VERSION "Accord 9G AU Radar BUS 1"

NS_ :

BS_:

BU_: RADAR ADAS EON

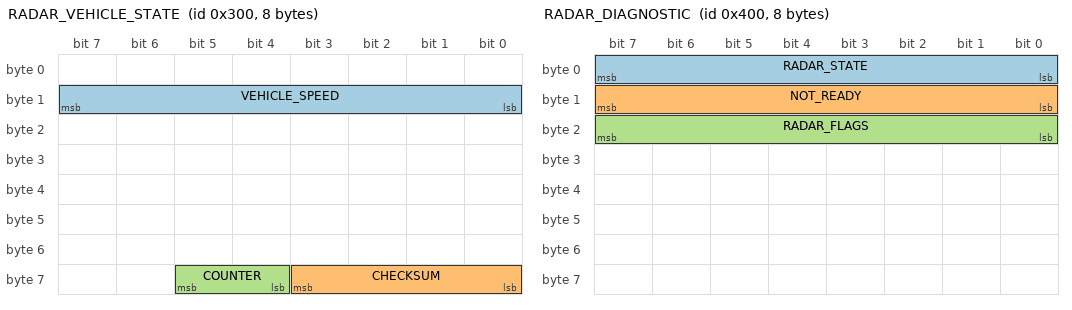
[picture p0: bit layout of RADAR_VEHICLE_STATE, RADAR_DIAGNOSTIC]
BO_ 768 RADAR_VEHICLE_STATE: 8 ADAS
 SG_ VEHICLE_SPEED : 15|8@0+ (1,0) [0|255] "kph" RADAR
 SG_ CHECKSUM : 59|4@0+ (1,0) [0|15] "" RADAR
 SG_ COUNTER : 61|2@0+ (1,0) [0|3] "" RADAR

BO_ 769 RADAR_VEHICLE_STATE2: 8 ADAS

BO_ 1024 RADAR_DIAGNOSTIC: 8 RADAR
 SG_ RADAR_STATE : 7|8@0+ (1,0) [0|255] "" EON
 SG_ NOT_READY : 15|8@0+ (1,0) [0|255] "" EON
 SG_ RADAR_FLAGS : 23|8@0+ (1,0) [0|255] "" EON

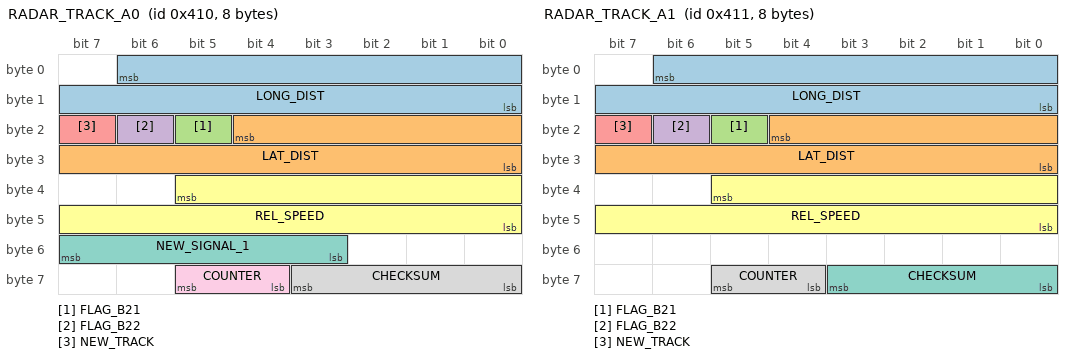
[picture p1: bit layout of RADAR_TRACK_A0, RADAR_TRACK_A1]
BO_ 1040 RADAR_TRACK_A0: 8 RADAR
 SG_ LONG_DIST : 6|15@0+ (0.0078125,0) [0|255.99] "m" EON
 SG_ LAT_DIST : 20|13@0- (0.0078125,0) [-32|32] "m" EON
 SG_ FLAG_B21 : 21|1@0+ (1,0) [0|1] "" EON
 SG_ FLAG_B22 : 22|1@0+ (1,0) [0|1] "" EON
 SG_ NEW_TRACK : 23|1@0+ (1,0) [0|1] "" EON
 SG_ REL_SPEED : 37|14@0- (0.0078125,0) [-64|64] "m/s" EON
 SG_ NEW_SIGNAL_1 : 55|5@0+ (1,0) [0|31] "" XXX
 SG_ CHECKSUM : 59|4@0+ (1,0) [0|15] "" EON
 SG_ COUNTER : 61|2@0+ (1,0) [0|3] "" EON

BO_ 1041 RADAR_TRACK_A1: 8 RADAR
 SG_ LONG_DIST : 6|15@0+ (0.0078125,0) [0|255.99] "m" EON
 SG_ LAT_DIST : 20|13@0- (0.0078125,0) [-32|32] "m" EON
 SG_ FLAG_B21 : 21|1@0+ (1,0) [0|1] "" EON
 SG_ FLAG_B22 : 22|1@0+ (1,0) [0|1] "" EON
 SG_ NEW_TRACK : 23|1@0+ (1,0) [0|1] "" EON
 SG_ REL_SPEED : 37|14@0- (0.0078125,0) [-64|64] "m/s" EON
 SG_ CHECKSUM : 59|4@0+ (1,0) [0|15] "" EON
 SG_ COUNTER : 61|2@0+ (1,0) [0|3] "" EON

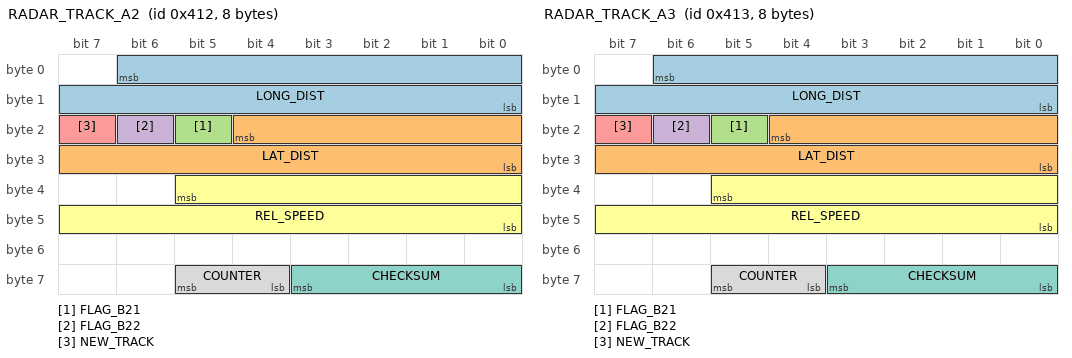
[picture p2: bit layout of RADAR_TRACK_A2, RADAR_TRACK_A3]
BO_ 1042 RADAR_TRACK_A2: 8 RADAR
 SG_ LONG_DIST : 6|15@0+ (0.0078125,0) [0|255.99] "m" EON
 SG_ LAT_DIST : 20|13@0- (0.0078125,0) [-32|32] "m" EON
 SG_ FLAG_B21 : 21|1@0+ (1,0) [0|1] "" EON
 SG_ FLAG_B22 : 22|1@0+ (1,0) [0|1] "" EON
 SG_ NEW_TRACK : 23|1@0+ (1,0) [0|1] "" EON
 SG_ REL_SPEED : 37|14@0- (0.0078125,0) [-64|64] "m/s" EON
 SG_ CHECKSUM : 59|4@0+ (1,0) [0|15] "" EON
 SG_ COUNTER : 61|2@0+ (1,0) [0|3] "" EON

BO_ 1043 RADAR_TRACK_A3: 8 RADAR
 SG_ LONG_DIST : 6|15@0+ (0.0078125,0) [0|255.99] "m" EON
 SG_ LAT_DIST : 20|13@0- (0.0078125,0) [-32|32] "m" EON
 SG_ FLAG_B21 : 21|1@0+ (1,0) [0|1] "" EON
 SG_ FLAG_B22 : 22|1@0+ (1,0) [0|1] "" EON
 SG_ NEW_TRACK : 23|1@0+ (1,0) [0|1] "" EON
 SG_ REL_SPEED : 37|14@0- (0.0078125,0) [-64|64] "m/s" EON
 SG_ CHECKSUM : 59|4@0+ (1,0) [0|15] "" EON
 SG_ COUNTER : 61|2@0+ (1,0) [0|3] "" EON

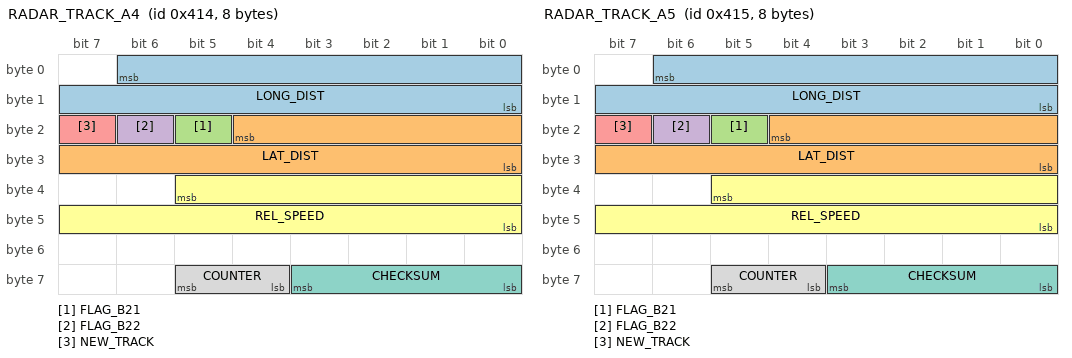
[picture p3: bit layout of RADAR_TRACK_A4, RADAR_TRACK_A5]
BO_ 1044 RADAR_TRACK_A4: 8 RADAR
 SG_ LONG_DIST : 6|15@0+ (0.0078125,0) [0|255.99] "m" EON
 SG_ LAT_DIST : 20|13@0- (0.0078125,0) [-32|32] "m" EON
 SG_ FLAG_B21 : 21|1@0+ (1,0) [0|1] "" EON
 SG_ FLAG_B22 : 22|1@0+ (1,0) [0|1] "" EON
 SG_ NEW_TRACK : 23|1@0+ (1,0) [0|1] "" EON
 SG_ REL_SPEED : 37|14@0- (0.0078125,0) [-64|64] "m/s" EON
 SG_ CHECKSUM : 59|4@0+ (1,0) [0|15] "" EON
 SG_ COUNTER : 61|2@0+ (1,0) [0|3] "" EON

BO_ 1045 RADAR_TRACK_A5: 8 RADAR
 SG_ LONG_DIST : 6|15@0+ (0.0078125,0) [0|255.99] "m" EON
 SG_ LAT_DIST : 20|13@0- (0.0078125,0) [-32|32] "m" EON
 SG_ FLAG_B21 : 21|1@0+ (1,0) [0|1] "" EON
 SG_ FLAG_B22 : 22|1@0+ (1,0) [0|1] "" EON
 SG_ NEW_TRACK : 23|1@0+ (1,0) [0|1] "" EON
 SG_ REL_SPEED : 37|14@0- (0.0078125,0) [-64|64] "m/s" EON
 SG_ CHECKSUM : 59|4@0+ (1,0) [0|15] "" EON
 SG_ COUNTER : 61|2@0+ (1,0) [0|3] "" EON

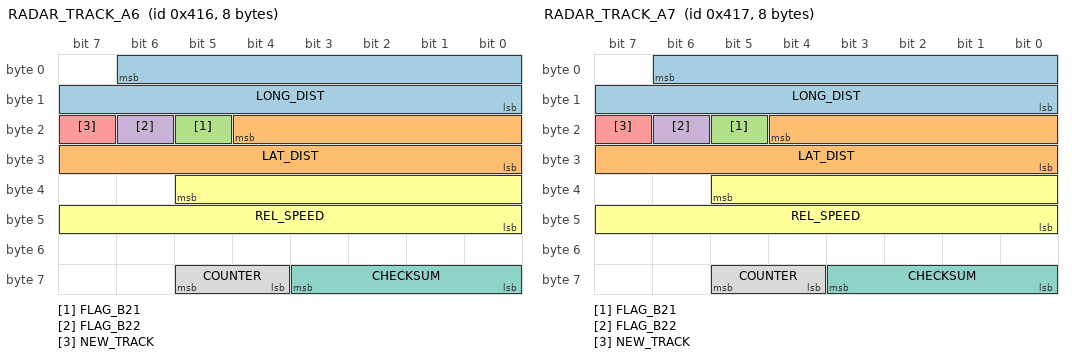
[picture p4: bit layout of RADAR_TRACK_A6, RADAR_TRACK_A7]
BO_ 1046 RADAR_TRACK_A6: 8 RADAR
 SG_ LONG_DIST : 6|15@0+ (0.0078125,0) [0|255.99] "m" EON
 SG_ LAT_DIST : 20|13@0- (0.0078125,0) [-32|32] "m" EON
 SG_ FLAG_B21 : 21|1@0+ (1,0) [0|1] "" EON
 SG_ FLAG_B22 : 22|1@0+ (1,0) [0|1] "" EON
 SG_ NEW_TRACK : 23|1@0+ (1,0) [0|1] "" EON
 SG_ REL_SPEED : 37|14@0- (0.0078125,0) [-64|64] "m/s" EON
 SG_ CHECKSUM : 59|4@0+ (1,0) [0|15] "" EON
 SG_ COUNTER : 61|2@0+ (1,0) [0|3] "" EON

BO_ 1047 RADAR_TRACK_A7: 8 RADAR
 SG_ LONG_DIST : 6|15@0+ (0.0078125,0) [0|255.99] "m" EON
 SG_ LAT_DIST : 20|13@0- (0.0078125,0) [-32|32] "m" EON
 SG_ FLAG_B21 : 21|1@0+ (1,0) [0|1] "" EON
 SG_ FLAG_B22 : 22|1@0+ (1,0) [0|1] "" EON
 SG_ NEW_TRACK : 23|1@0+ (1,0) [0|1] "" EON
 SG_ REL_SPEED : 37|14@0- (0.0078125,0) [-64|64] "m/s" EON
 SG_ CHECKSUM : 59|4@0+ (1,0) [0|15] "" EON
 SG_ COUNTER : 61|2@0+ (1,0) [0|3] "" EON

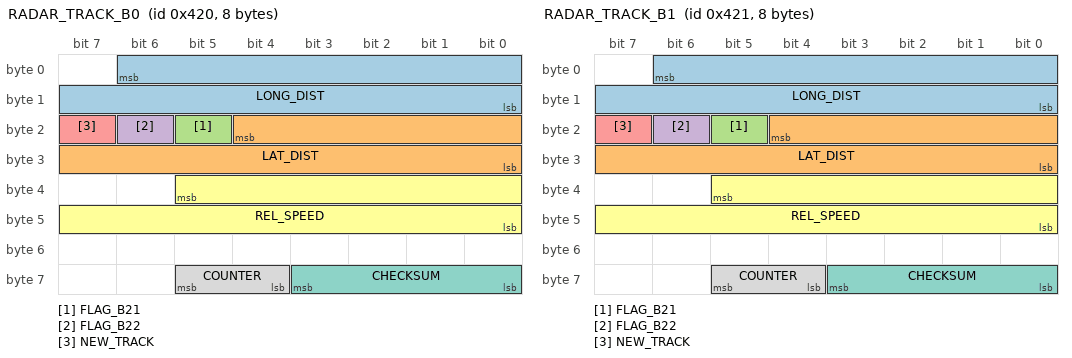
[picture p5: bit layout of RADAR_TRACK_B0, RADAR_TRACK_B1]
BO_ 1056 RADAR_TRACK_B0: 8 RADAR
 SG_ LONG_DIST : 6|15@0+ (0.0078125,0) [0|255.99] "m" EON
 SG_ LAT_DIST : 20|13@0- (0.0078125,0) [-32|32] "m" EON
 SG_ FLAG_B21 : 21|1@0+ (1,0) [0|1] "" EON
 SG_ FLAG_B22 : 22|1@0+ (1,0) [0|1] "" EON
 SG_ NEW_TRACK : 23|1@0+ (1,0) [0|1] "" EON
 SG_ REL_SPEED : 37|14@0- (0.0078125,0) [-64|64] "m/s" EON
 SG_ CHECKSUM : 59|4@0+ (1,0) [0|15] "" EON
 SG_ COUNTER : 61|2@0+ (1,0) [0|3] "" EON

BO_ 1057 RADAR_TRACK_B1: 8 RADAR
 SG_ LONG_DIST : 6|15@0+ (0.0078125,0) [0|255.99] "m" EON
 SG_ LAT_DIST : 20|13@0- (0.0078125,0) [-32|32] "m" EON
 SG_ FLAG_B21 : 21|1@0+ (1,0) [0|1] "" EON
 SG_ FLAG_B22 : 22|1@0+ (1,0) [0|1] "" EON
 SG_ NEW_TRACK : 23|1@0+ (1,0) [0|1] "" EON
 SG_ REL_SPEED : 37|14@0- (0.0078125,0) [-64|64] "m/s" EON
 SG_ CHECKSUM : 59|4@0+ (1,0) [0|15] "" EON
 SG_ COUNTER : 61|2@0+ (1,0) [0|3] "" EON

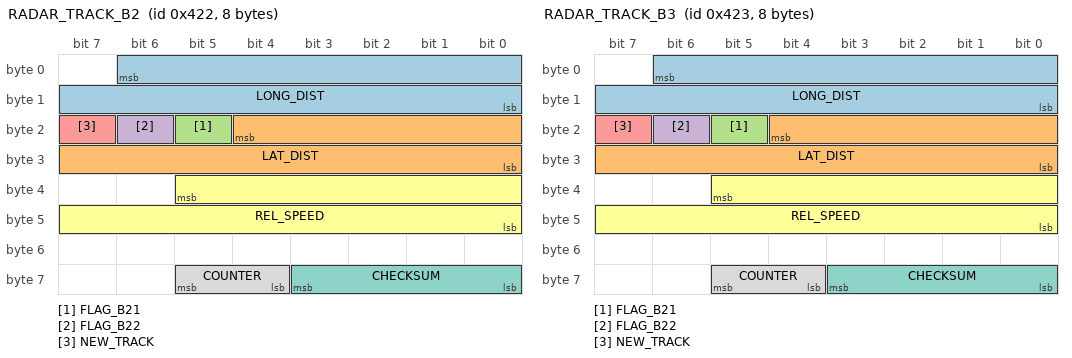
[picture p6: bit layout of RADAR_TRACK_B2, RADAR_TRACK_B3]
BO_ 1058 RADAR_TRACK_B2: 8 RADAR
 SG_ LONG_DIST : 6|15@0+ (0.0078125,0) [0|255.99] "m" EON
 SG_ LAT_DIST : 20|13@0- (0.0078125,0) [-32|32] "m" EON
 SG_ FLAG_B21 : 21|1@0+ (1,0) [0|1] "" EON
 SG_ FLAG_B22 : 22|1@0+ (1,0) [0|1] "" EON
 SG_ NEW_TRACK : 23|1@0+ (1,0) [0|1] "" EON
 SG_ REL_SPEED : 37|14@0- (0.0078125,0) [-64|64] "m/s" EON
 SG_ CHECKSUM : 59|4@0+ (1,0) [0|15] "" EON
 SG_ COUNTER : 61|2@0+ (1,0) [0|3] "" EON

BO_ 1059 RADAR_TRACK_B3: 8 RADAR
 SG_ LONG_DIST : 6|15@0+ (0.0078125,0) [0|255.99] "m" EON
 SG_ LAT_DIST : 20|13@0- (0.0078125,0) [-32|32] "m" EON
 SG_ FLAG_B21 : 21|1@0+ (1,0) [0|1] "" EON
 SG_ FLAG_B22 : 22|1@0+ (1,0) [0|1] "" EON
 SG_ NEW_TRACK : 23|1@0+ (1,0) [0|1] "" EON
 SG_ REL_SPEED : 37|14@0- (0.0078125,0) [-64|64] "m/s" EON
 SG_ CHECKSUM : 59|4@0+ (1,0) [0|15] "" EON
 SG_ COUNTER : 61|2@0+ (1,0) [0|3] "" EON

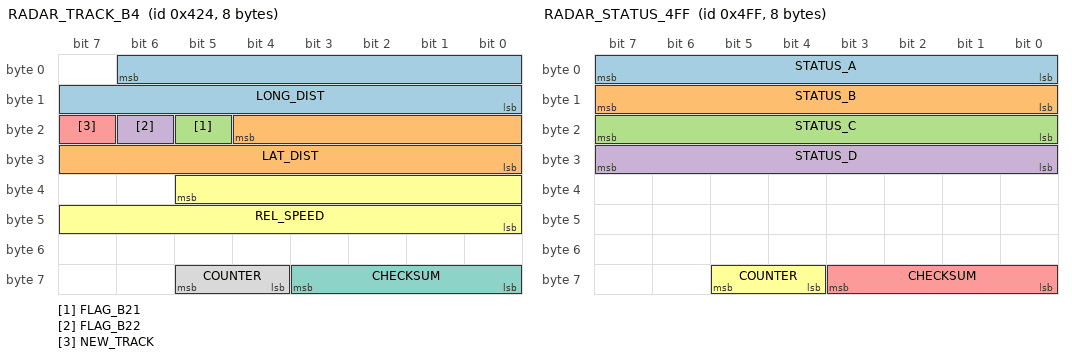
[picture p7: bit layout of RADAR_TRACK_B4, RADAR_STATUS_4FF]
BO_ 1060 RADAR_TRACK_B4: 8 RADAR
 SG_ LONG_DIST : 6|15@0+ (0.0078125,0) [0|255.99] "m" EON
 SG_ LAT_DIST : 20|13@0- (0.0078125,0) [-32|32] "m" EON
 SG_ FLAG_B21 : 21|1@0+ (1,0) [0|1] "" EON
 SG_ FLAG_B22 : 22|1@0+ (1,0) [0|1] "" EON
 SG_ NEW_TRACK : 23|1@0+ (1,0) [0|1] "" EON
 SG_ REL_SPEED : 37|14@0- (0.0078125,0) [-64|64] "m/s" EON
 SG_ CHECKSUM : 59|4@0+ (1,0) [0|15] "" EON
 SG_ COUNTER : 61|2@0+ (1,0) [0|3] "" EON

BO_ 1279 RADAR_STATUS_4FF: 8 RADAR
 SG_ STATUS_A : 7|8@0+ (1,0) [0|255] "" EON
 SG_ STATUS_B : 15|8@0+ (1,0) [0|111] "" EON
 SG_ STATUS_C : 23|8@0+ (1,0) [0|255] "" EON
 SG_ STATUS_D : 31|8@0+ (1,0) [0|255] "" EON
 SG_ CHECKSUM : 59|4@0+ (1,0) [0|15] "" EON
 SG_ COUNTER : 61|2@0+ (1,0) [0|3] "" EON
